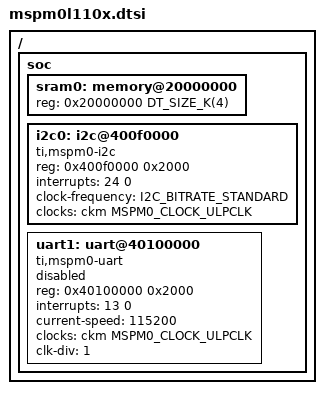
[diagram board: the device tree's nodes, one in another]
/*
 * Copyright (c) 2025 Texas Instruments
 * Copyright (c) 2025 Linumiz GmbH
 *
 * SPDX-License-Identifier: Apache-2.0
 */

#include <mem.h>
#include <zephyr/dt-bindings/i2c/i2c.h>
#include <ti/mspm0/l/mspm0l.dtsi>

/delete-node/ &gpiob;
/delete-node/ &gpioc;

/ {
	soc {
		sram0: memory@20000000 {
			reg = <0x20000000 DT_SIZE_K(4)>;
		};

		i2c0: i2c@400f0000 {
			compatible = "ti,mspm0-i2c";
			reg = <0x400f0000 0x2000>;
			interrupts = <24 0>;
			clock-frequency = <I2C_BITRATE_STANDARD>;
			clocks = <&ckm MSPM0_CLOCK_ULPCLK>;
			#address-cells = <1>;
			#size-cells = <0>;
		};

		uart1: uart@40100000 {
			compatible = "ti,mspm0-uart";
			reg = <0x40100000 0x2000>;
			interrupts = <13 0>;
			current-speed = <115200>;
			clocks = <&ckm MSPM0_CLOCK_ULPCLK>;
			clk-div = <1>;
			status = "disabled";
		};
	};
};
